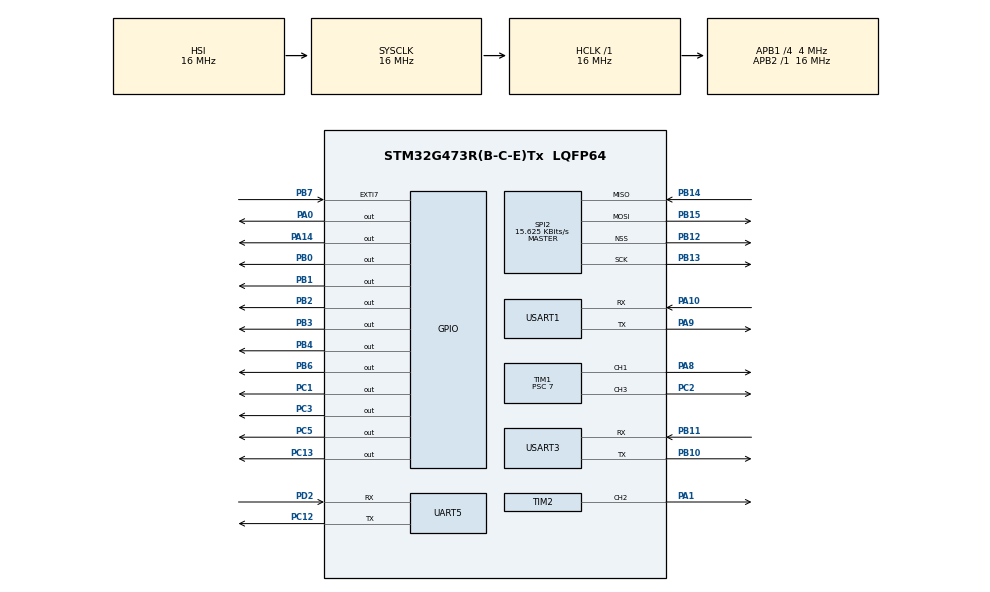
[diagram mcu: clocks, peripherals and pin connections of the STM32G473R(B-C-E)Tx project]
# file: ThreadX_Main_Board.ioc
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Dma.Request0=UART5_RX
Dma.UART5_RX.0.Direction=DMA_PERIPH_TO_MEMORY
Dma.UART5_RX.0.EventEnable=DISABLE
Dma.UART5_RX.0.Instance=DMA1_Channel1
Dma.UART5_RX.0.MemDataAlignment=DMA_MDATAALIGN_BYTE
Dma.UART5_RX.0.MemInc=DMA_MINC_ENABLE
Dma.UART5_RX.0.Mode=DMA_NORMAL
Dma.UART5_RX.0.PeriphDataAlignment=DMA_PDATAALIGN_BYTE
Dma.UART5_RX.0.PeriphInc=DMA_PINC_DISABLE
Dma.UART5_RX.0.Polarity=HAL_DMAMUX_REQ_GEN_RISING
Dma.UART5_RX.0.Priority=DMA_PRIORITY_LOW
Dma.UART5_RX.0.RequestNumber=1
Dma.UART5_RX.0.SignalID=NONE
Dma.UART5_RX.0.SyncEnable=DISABLE
Dma.UART5_RX.0.SyncPolarity=HAL_DMAMUX_SYNC_NO_EVENT
Dma.UART5_RX.0.SyncRequestNumber=1
Dma.UART5_RX.0.SyncSignalID=NONE
Mcu.Family=STM32G4
Mcu.Name=STM32G473R(B-C-E)Tx
Mcu.Package=LQFP64
NVIC.DMA1_Channel1_IRQn=true\:0\:0\:false\:false\:true\:true\:false\:true\:true
NVIC.EXTI9_5_IRQn=true\:0\:0\:false\:false\:true\:false\:true\:true\:true
NVIC.PriorityGroup=NVIC_PRIORITYGROUP_4
NVIC.TIM6_DAC_IRQn=true\:15\:0\:false\:false\:true\:false\:false\:true\:true
NVIC.TimeBase=TIM6_DAC_IRQn
NVIC.TimeBaseIP=TIM6
PA0.Signal=GPIO_Output
PA1.Signal=S_TIM2_CH2
PA10.Mode=Asynchronous
PA10.Signal=USART1_RX
PA14.Signal=GPIO_Output
PA4.Signal=SPI1_NSS
PA8.Signal=S_TIM1_CH1
PA9.Mode=Asynchronous
PA9.Signal=USART1_TX
PB0.Signal=GPIO_Output
PB1.Signal=GPIO_Output
PB10.Mode=Asynchronous
PB10.Signal=USART3_TX
PB11.Mode=Asynchronous
PB11.Signal=USART3_RX
PB12.Mode=NSS_Signal_Hard_Output
PB12.Signal=SPI2_NSS
PB13.Mode=Full_Duplex_Master
PB13.Signal=SPI2_SCK
PB14.Mode=Full_Duplex_Master
PB14.Signal=SPI2_MISO
PB15.Mode=Full_Duplex_Master
PB15.Signal=SPI2_MOSI
PB2.Signal=GPIO_Output
PB3.GPIO_PuPd=GPIO_PULLDOWN
PB3.Signal=GPIO_Output
PB4.Signal=GPIO_Output
PB5.Signal=SPI1_MOSI
PB6.Signal=GPIO_Output
PB7.Signal=GPXTI7
PB9.Signal=I2C1_SDA
PC1.Signal=GPIO_Output
PC12.Mode=Asynchronous
PC12.Signal=UART5_TX
PC13.Signal=GPIO_Output
PC2.Signal=S_TIM1_CH3
PC3.Signal=GPIO_Output
PC5.Signal=GPIO_Output
PD2.Mode=Asynchronous
PD2.Signal=UART5_RX
PF0-OSC_IN.Mode=HSE-External-Oscillator
PF0-OSC_IN.Signal=RCC_OSC_IN
PF1-OSC_OUT.Mode=HSE-External-Oscillator
PF1-OSC_OUT.Signal=RCC_OSC_OUT
ProjectManager.HeapSize=0x200
ProjectManager.StackSize=0x400
ProjectManager.TargetToolchain=STM32CubeIDE
RCC.ADC12Freq_Value=16000000
RCC.ADC345Freq_Value=16000000
RCC.AHBFreq_Value=16000000
RCC.APB1CLKDivider=RCC_HCLK_DIV4
RCC.APB1Freq_Value=4000000
RCC.APB1TimFreq_Value=8000000
RCC.APB2Freq_Value=16000000
RCC.APB2TimFreq_Value=16000000
RCC.CortexFreq_Value=16000000
RCC.EXTERNAL_CLOCK_VALUE=12288000
RCC.HCLKFreq_Value=16000000
RCC.HSE_VALUE=8000000
RCC.HSI48_VALUE=48000000
RCC.HSI_VALUE=16000000
RCC.LSE_VALUE=32768
RCC.SYSCLKFreq_VALUE=16000000
RCC.USBFreq_Value=64000000
RCC.VCOOutputFreq_Value=128000000
SH.S_TIM1_CH1.0=TIM1_CH1,PWM Generation1 CH1
SH.S_TIM1_CH3.0=TIM1_CH3,PWM Generation3 CH3
SH.S_TIM2_CH2.0=TIM2_CH2,PWM Generation2 CH2
SPI2.BaudRatePrescaler=SPI_BAUDRATEPRESCALER_256
SPI2.CalculateBaudRate=15.625 KBits/s
SPI2.DataSize=SPI_DATASIZE_8BIT
SPI2.Direction=SPI_DIRECTION_2LINES
SPI2.Mode=SPI_MODE_MASTER
SPI2.VirtualNSS=VM_NSSHARD
SPI2.VirtualType=VM_MASTER
STMicroelectronics.X-CUBE-AZRTOS-G4.2.0.0.TX_TIMER_TICKS_PER_SECOND=1000
STMicroelectronics.X-CUBE-AZRTOS-G4.2.0.0.ThreadXCcRTOSJjThreadXJjCore=true
STMicroelectronics.X-CUBE-AZRTOS-G4.2.0.0_IsAnAzureRtosMw=true
TIM1.Channel-PWM\ Generation1\ CH1=TIM_CHANNEL_1
TIM1.Channel-PWM\ Generation3\ CH3=TIM_CHANNEL_3
TIM1.PeriodNoDither=255
TIM1.Prescaler=7
TIM2.Channel-PWM\ Generation2\ CH2=TIM_CHANNEL_2
TIM2.PeriodNoDither=255
TIM3.PeriodNoDither=255
TIM3.Prescaler=0
TIM5.PeriodNoDither=255
USART1.VirtualMode-Asynchronous=VM_ASYNC
USART3.VirtualMode-Asynchronous=VM_ASYNC
VP_STMicroelectronics.X-CUBE-AZRTOS-G4_VS_RTOSJjThreadX_6.2.0_2.0.0.Mode=RTOSJjThreadX
VP_SYS_VS_DBSignals.Mode=DisableDeadBatterySignals
VP_SYS_VS_tim6.Mode=TIM6
VP_TIM1_VS_ClockSourceINT.Mode=Internal
VP_TIM3_VS_ClockSourceINT.Mode=Internal
VP_TIM5_VS_ClockSourceINT.Mode=Internal
board=custom

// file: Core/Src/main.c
/* USER CODE BEGIN Header */
/**
 ******************************************************************************
 * @file           : main.c
 * @brief          : Main program body
 ******************************************************************************
 * @attention
 *
 * Copyright (c) 2024 STMicroelectronics.
 * All rights reserved.
 *
 * This software is licensed under terms that can be found in the LICENSE file
 * in the root directory of this software component.
 * If no LICENSE file comes with this software, it is provided AS-IS.
 *
 ******************************************************************************
 */
/* USER CODE END Header */
#include "app_threadx.h"
#include "main.h"

SPI_HandleTypeDef hspi2;

TIM_HandleTypeDef htim1;
TIM_HandleTypeDef htim2;
TIM_HandleTypeDef htim3;
TIM_HandleTypeDef htim5;

UART_HandleTypeDef huart5;
UART_HandleTypeDef huart1;
UART_HandleTypeDef huart3;
DMA_HandleTypeDef hdma_uart5_rx;

void SystemClock_Config(void);
static void MX_GPIO_Init(void);
static void MX_DMA_Init(void);
static void MX_SPI2_Init(void);
static void MX_USART3_UART_Init(void);
static void MX_USART1_UART_Init(void);
static void MX_UART5_Init(void);
static void MX_TIM1_Init(void);
static void MX_TIM3_Init(void);
static void MX_TIM2_Init(void);
static void MX_TIM5_Init(void);

/* USER CODE BEGIN 0 */
void __io_putchar(char ch) {
	HAL_UART_Transmit(&huart1, (uint8_t *)&ch, 1, 10);
}
/* USER CODE END 0 */

int main(void)
{

  /* MCU Configuration--------------------------------------------------------*/

  /* Reset of all peripherals, Initializes the Flash interface and the Systick. */
  HAL_Init();

  /* Configure the system clock */
  SystemClock_Config();

  /* Initialize all configured peripherals */
  MX_GPIO_Init();
  MX_DMA_Init();
  MX_SPI2_Init();
  MX_USART3_UART_Init();
  MX_USART1_UART_Init();
  MX_UART5_Init();
  MX_TIM1_Init();
  MX_TIM3_Init();
  MX_TIM2_Init();
  MX_TIM5_Init();

  MX_ThreadX_Init();

  /* We should never get here as control is now taken by the scheduler */

  /* Infinite loop */
	while (1)
	{

	}
}

void SystemClock_Config(void)
{
  RCC_OscInitTypeDef RCC_OscInitStruct = {0};
  RCC_ClkInitTypeDef RCC_ClkInitStruct = {0};

  /** Configure the main internal regulator output voltage
  */
  HAL_PWREx_ControlVoltageScaling(PWR_REGULATOR_VOLTAGE_SCALE1);

  /** Initializes the RCC Oscillators according to the specified parameters
  * in the RCC_OscInitTypeDef structure.
  */
  RCC_OscInitStruct.OscillatorType = RCC_OSCILLATORTYPE_HSI;
  RCC_OscInitStruct.HSIState = RCC_HSI_ON;
  RCC_OscInitStruct.HSICalibrationValue = RCC_HSICALIBRATION_DEFAULT;
  RCC_OscInitStruct.PLL.PLLState = RCC_PLL_NONE;
  if (HAL_RCC_OscConfig(&RCC_OscInitStruct) != HAL_OK)
  {
    Error_Handler();
  }

  /** Initializes the CPU, AHB and APB buses clocks
  */
  RCC_ClkInitStruct.ClockType = RCC_CLOCKTYPE_HCLK|RCC_CLOCKTYPE_SYSCLK
                              |RCC_CLOCKTYPE_PCLK1|RCC_CLOCKTYPE_PCLK2;
  RCC_ClkInitStruct.SYSCLKSource = RCC_SYSCLKSOURCE_HSI;
  RCC_ClkInitStruct.AHBCLKDivider = RCC_SYSCLK_DIV1;
  RCC_ClkInitStruct.APB1CLKDivider = RCC_HCLK_DIV4;
  RCC_ClkInitStruct.APB2CLKDivider = RCC_HCLK_DIV1;

  if (HAL_RCC_ClockConfig(&RCC_ClkInitStruct, FLASH_LATENCY_0) != HAL_OK)
  {
    Error_Handler();
  }
}

static void MX_SPI2_Init(void)
{

  /* SPI2 parameter configuration*/
  hspi2.Instance = SPI2;
  hspi2.Init.Mode = SPI_MODE_MASTER;
  hspi2.Init.Direction = SPI_DIRECTION_2LINES;
  hspi2.Init.DataSize = SPI_DATASIZE_8BIT;
  hspi2.Init.CLKPolarity = SPI_POLARITY_LOW;
  hspi2.Init.CLKPhase = SPI_PHASE_1EDGE;
  hspi2.Init.NSS = SPI_NSS_HARD_OUTPUT;
  hspi2.Init.BaudRatePrescaler = SPI_BAUDRATEPRESCALER_256;
  hspi2.Init.FirstBit = SPI_FIRSTBIT_MSB;
  hspi2.Init.TIMode = SPI_TIMODE_DISABLE;
  hspi2.Init.CRCCalculation = SPI_CRCCALCULATION_DISABLE;
  hspi2.Init.CRCPolynomial = 7;
  hspi2.Init.CRCLength = SPI_CRC_LENGTH_DATASIZE;
  hspi2.Init.NSSPMode = SPI_NSS_PULSE_ENABLE;
  if (HAL_SPI_Init(&hspi2) != HAL_OK)
  {
    Error_Handler();
  }

}

static void MX_TIM1_Init(void)
{

  TIM_ClockConfigTypeDef sClockSourceConfig = {0};
  TIM_MasterConfigTypeDef sMasterConfig = {0};
  TIM_OC_InitTypeDef sConfigOC = {0};
  TIM_BreakDeadTimeConfigTypeDef sBreakDeadTimeConfig = {0};

  htim1.Instance = TIM1;
  htim1.Init.Prescaler = 7;
  htim1.Init.CounterMode = TIM_COUNTERMODE_UP;
  htim1.Init.Period = 255;
  htim1.Init.ClockDivision = TIM_CLOCKDIVISION_DIV1;
  htim1.Init.RepetitionCounter = 0;
  htim1.Init.AutoReloadPreload = TIM_AUTORELOAD_PRELOAD_DISABLE;
  if (HAL_TIM_Base_Init(&htim1) != HAL_OK)
  {
    Error_Handler();
  }
  sClockSourceConfig.ClockSource = TIM_CLOCKSOURCE_INTERNAL;
  if (HAL_TIM_ConfigClockSource(&htim1, &sClockSourceConfig) != HAL_OK)
  {
    Error_Handler();
  }
  if (HAL_TIM_PWM_Init(&htim1) != HAL_OK)
  {
    Error_Handler();
  }
  sMasterConfig.MasterOutputTrigger = TIM_TRGO_RESET;
  sMasterConfig.MasterOutputTrigger2 = TIM_TRGO2_RESET;
  sMasterConfig.MasterSlaveMode = TIM_MASTERSLAVEMODE_DISABLE;
  if (HAL_TIMEx_MasterConfigSynchronization(&htim1, &sMasterConfig) != HAL_OK)
  {
    Error_Handler();
  }
  sConfigOC.OCMode = TIM_OCMODE_PWM1;
  sConfigOC.Pulse = 0;
  sConfigOC.OCPolarity = TIM_OCPOLARITY_HIGH;
  sConfigOC.OCNPolarity = TIM_OCNPOLARITY_HIGH;
  sConfigOC.OCFastMode = TIM_OCFAST_DISABLE;
  sConfigOC.OCIdleState = TIM_OCIDLESTATE_RESET;
  sConfigOC.OCNIdleState = TIM_OCNIDLESTATE_RESET;
  if (HAL_TIM_PWM_ConfigChannel(&htim1, &sConfigOC, TIM_CHANNEL_1) != HAL_OK)
  {
    Error_Handler();
  }
  if (HAL_TIM_PWM_ConfigChannel(&htim1, &sConfigOC, TIM_CHANNEL_3) != HAL_OK)
  {
    Error_Handler();
  }
  sBreakDeadTimeConfig.OffStateRunMode = TIM_OSSR_DISABLE;
  sBreakDeadTimeConfig.OffStateIDLEMode = TIM_OSSI_DISABLE;
  sBreakDeadTimeConfig.LockLevel = TIM_LOCKLEVEL_OFF;
  sBreakDeadTimeConfig.DeadTime = 0;
  sBreakDeadTimeConfig.BreakState = TIM_BREAK_DISABLE;
  sBreakDeadTimeConfig.BreakPolarity = TIM_BREAKPOLARITY_HIGH;
  sBreakDeadTimeConfig.BreakFilter = 0;
  sBreakDeadTimeConfig.BreakAFMode = TIM_BREAK_AFMODE_INPUT;
  sBreakDeadTimeConfig.Break2State = TIM_BREAK2_DISABLE;
  sBreakDeadTimeConfig.Break2Polarity = TIM_BREAK2POLARITY_HIGH;
  sBreakDeadTimeConfig.Break2Filter = 0;
  sBreakDeadTimeConfig.Break2AFMode = TIM_BREAK_AFMODE_INPUT;
  sBreakDeadTimeConfig.AutomaticOutput = TIM_AUTOMATICOUTPUT_DISABLE;
  if (HAL_TIMEx_ConfigBreakDeadTime(&htim1, &sBreakDeadTimeConfig) != HAL_OK)
  {
    Error_Handler();
  }
  HAL_TIM_MspPostInit(&htim1);

}

static void MX_TIM2_Init(void)
{

  TIM_MasterConfigTypeDef sMasterConfig = {0};
  TIM_OC_InitTypeDef sConfigOC = {0};

  htim2.Instance = TIM2;
  htim2.Init.Prescaler = 0;
  htim2.Init.CounterMode = TIM_COUNTERMODE_UP;
  htim2.Init.Period = 255;
  htim2.Init.ClockDivision = TIM_CLOCKDIVISION_DIV1;
  htim2.Init.AutoReloadPreload = TIM_AUTORELOAD_PRELOAD_DISABLE;
  if (HAL_TIM_PWM_Init(&htim2) != HAL_OK)
  {
    Error_Handler();
  }
  sMasterConfig.MasterOutputTrigger = TIM_TRGO_RESET;
  sMasterConfig.MasterSlaveMode = TIM_MASTERSLAVEMODE_DISABLE;
  if (HAL_TIMEx_MasterConfigSynchronization(&htim2, &sMasterConfig) != HAL_OK)
  {
    Error_Handler();
  }
  sConfigOC.OCMode = TIM_OCMODE_PWM1;
  sConfigOC.Pulse = 0;
  sConfigOC.OCPolarity = TIM_OCPOLARITY_HIGH;
  sConfigOC.OCFastMode = TIM_OCFAST_DISABLE;
  if (HAL_TIM_PWM_ConfigChannel(&htim2, &sConfigOC, TIM_CHANNEL_2) != HAL_OK)
  {
    Error_Handler();
  }
  HAL_TIM_MspPostInit(&htim2);

}

static void MX_TIM3_Init(void)
{

  TIM_ClockConfigTypeDef sClockSourceConfig = {0};
  TIM_MasterConfigTypeDef sMasterConfig = {0};

  htim3.Instance = TIM3;
  htim3.Init.Prescaler = 0;
  htim3.Init.CounterMode = TIM_COUNTERMODE_UP;
  htim3.Init.Period = 255;
  htim3.Init.ClockDivision = TIM_CLOCKDIVISION_DIV1;
  htim3.Init.AutoReloadPreload = TIM_AUTORELOAD_PRELOAD_DISABLE;
  if (HAL_TIM_Base_Init(&htim3) != HAL_OK)
  {
    Error_Handler();
  }
  sClockSourceConfig.ClockSource = TIM_CLOCKSOURCE_INTERNAL;
  if (HAL_TIM_ConfigClockSource(&htim3, &sClockSourceConfig) != HAL_OK)
  {
    Error_Handler();
  }
  sMasterConfig.MasterOutputTrigger = TIM_TRGO_RESET;
  sMasterConfig.MasterSlaveMode = TIM_MASTERSLAVEMODE_DISABLE;
  if (HAL_TIMEx_MasterConfigSynchronization(&htim3, &sMasterConfig) != HAL_OK)
  {
    Error_Handler();
  }

}

static void MX_TIM5_Init(void)
{

  TIM_ClockConfigTypeDef sClockSourceConfig = {0};
  TIM_MasterConfigTypeDef sMasterConfig = {0};

  htim5.Instance = TIM5;
  htim5.Init.Prescaler = 0;
  htim5.Init.CounterMode = TIM_COUNTERMODE_UP;
  htim5.Init.Period = 255;
  htim5.Init.ClockDivision = TIM_CLOCKDIVISION_DIV1;
  htim5.Init.AutoReloadPreload = TIM_AUTORELOAD_PRELOAD_DISABLE;
  if (HAL_TIM_Base_Init(&htim5) != HAL_OK)
  {
    Error_Handler();
  }
  sClockSourceConfig.ClockSource = TIM_CLOCKSOURCE_INTERNAL;
  if (HAL_TIM_ConfigClockSource(&htim5, &sClockSourceConfig) != HAL_OK)
  {
    Error_Handler();
  }
  sMasterConfig.MasterOutputTrigger = TIM_TRGO_RESET;
  sMasterConfig.MasterSlaveMode = TIM_MASTERSLAVEMODE_DISABLE;
  if (HAL_TIMEx_MasterConfigSynchronization(&htim5, &sMasterConfig) != HAL_OK)
  {
    Error_Handler();
  }

}

static void MX_UART5_Init(void)
{

  huart5.Instance = UART5;
  huart5.Init.BaudRate = 115200;
  huart5.Init.WordLength = UART_WORDLENGTH_8B;
  huart5.Init.StopBits = UART_STOPBITS_1;
  huart5.Init.Parity = UART_PARITY_NONE;
  huart5.Init.Mode = UART_MODE_TX_RX;
  huart5.Init.HwFlowCtl = UART_HWCONTROL_NONE;
  huart5.Init.OverSampling = UART_OVERSAMPLING_16;
  huart5.Init.OneBitSampling = UART_ONE_BIT_SAMPLE_DISABLE;
  huart5.Init.ClockPrescaler = UART_PRESCALER_DIV1;
  huart5.AdvancedInit.AdvFeatureInit = UART_ADVFEATURE_NO_INIT;
  if (HAL_UART_Init(&huart5) != HAL_OK)
  {
    Error_Handler();
  }
  if (HAL_UARTEx_SetTxFifoThreshold(&huart5, UART_TXFIFO_THRESHOLD_1_8) != HAL_OK)
  {
    Error_Handler();
  }
  if (HAL_UARTEx_SetRxFifoThreshold(&huart5, UART_RXFIFO_THRESHOLD_1_8) != HAL_OK)
  {
    Error_Handler();
  }
  if (HAL_UARTEx_DisableFifoMode(&huart5) != HAL_OK)
  {
    Error_Handler();
  }

}

static void MX_USART1_UART_Init(void)
{

  huart1.Instance = USART1;
  huart1.Init.BaudRate = 115200;
  huart1.Init.WordLength = UART_WORDLENGTH_8B;
  huart1.Init.StopBits = UART_STOPBITS_1;
  huart1.Init.Parity = UART_PARITY_NONE;
  huart1.Init.Mode = UART_MODE_TX_RX;
  huart1.Init.HwFlowCtl = UART_HWCONTROL_NONE;
  huart1.Init.OverSampling = UART_OVERSAMPLING_16;
  huart1.Init.OneBitSampling = UART_ONE_BIT_SAMPLE_DISABLE;
  huart1.Init.ClockPrescaler = UART_PRESCALER_DIV1;
  huart1.AdvancedInit.AdvFeatureInit = UART_ADVFEATURE_NO_INIT;
  if (HAL_UART_Init(&huart1) != HAL_OK)
  {
    Error_Handler();
  }
  if (HAL_UARTEx_SetTxFifoThreshold(&huart1, UART_TXFIFO_THRESHOLD_1_8) != HAL_OK)
  {
    Error_Handler();
  }
  if (HAL_UARTEx_SetRxFifoThreshold(&huart1, UART_RXFIFO_THRESHOLD_1_8) != HAL_OK)
  {
    Error_Handler();
  }
  if (HAL_UARTEx_DisableFifoMode(&huart1) != HAL_OK)
  {
    Error_Handler();
  }

}

static void MX_USART3_UART_Init(void)
{

  huart3.Instance = USART3;
  huart3.Init.BaudRate = 115200;
  huart3.Init.WordLength = UART_WORDLENGTH_8B;
  huart3.Init.StopBits = UART_STOPBITS_1;
  huart3.Init.Parity = UART_PARITY_NONE;
  huart3.Init.Mode = UART_MODE_TX_RX;
  huart3.Init.HwFlowCtl = UART_HWCONTROL_NONE;
  huart3.Init.OverSampling = UART_OVERSAMPLING_16;
  huart3.Init.OneBitSampling = UART_ONE_BIT_SAMPLE_DISABLE;
  huart3.Init.ClockPrescaler = UART_PRESCALER_DIV1;
  huart3.AdvancedInit.AdvFeatureInit = UART_ADVFEATURE_NO_INIT;
  if (HAL_UART_Init(&huart3) != HAL_OK)
  {
    Error_Handler();
  }
  if (HAL_UARTEx_SetTxFifoThreshold(&huart3, UART_TXFIFO_THRESHOLD_1_8) != HAL_OK)
  {
    Error_Handler();
  }
  if (HAL_UARTEx_SetRxFifoThreshold(&huart3, UART_RXFIFO_THRESHOLD_1_8) != HAL_OK)
  {
    Error_Handler();
  }
  if (HAL_UARTEx_DisableFifoMode(&huart3) != HAL_OK)
  {
    Error_Handler();
  }

}

static void MX_DMA_Init(void)
{

  /* DMA controller clock enable */
  __HAL_RCC_DMAMUX1_CLK_ENABLE();
  __HAL_RCC_DMA1_CLK_ENABLE();

  /* DMA interrupt init */
  /* DMA1_Channel1_IRQn interrupt configuration */
  HAL_NVIC_SetPriority(DMA1_Channel1_IRQn, 0, 0);
  HAL_NVIC_EnableIRQ(DMA1_Channel1_IRQn);

}

static void MX_GPIO_Init(void)
{
  GPIO_InitTypeDef GPIO_InitStruct = {0};

  /* GPIO Ports Clock Enable */
  __HAL_RCC_GPIOC_CLK_ENABLE();
  __HAL_RCC_GPIOF_CLK_ENABLE();
  __HAL_RCC_GPIOA_CLK_ENABLE();
  __HAL_RCC_GPIOB_CLK_ENABLE();
  __HAL_RCC_GPIOD_CLK_ENABLE();

  /*Configure GPIO pin Output Level */
  HAL_GPIO_WritePin(GPIOC, GPIO_PIN_13|GPIO_PIN_1|GPIO_PIN_3|GPIO_PIN_5, GPIO_PIN_RESET);

  /*Configure GPIO pin Output Level */
  HAL_GPIO_WritePin(GPIOA, GPIO_PIN_0|GPIO_PIN_14, GPIO_PIN_RESET);

  /*Configure GPIO pin Output Level */
  HAL_GPIO_WritePin(GPIOB, GPIO_PIN_0|GPIO_PIN_1|GPIO_PIN_2|GPIO_PIN_3
                          |GPIO_PIN_4|GPIO_PIN_6, GPIO_PIN_RESET);

  /*Configure GPIO pins : PC13 PC1 PC3 PC5 */
  GPIO_InitStruct.Pin = GPIO_PIN_13|GPIO_PIN_1|GPIO_PIN_3|GPIO_PIN_5;
  GPIO_InitStruct.Mode = GPIO_MODE_OUTPUT_PP;
  GPIO_InitStruct.Pull = GPIO_NOPULL;
  GPIO_InitStruct.Speed = GPIO_SPEED_FREQ_LOW;
  HAL_GPIO_Init(GPIOC, &GPIO_InitStruct);

  /*Configure GPIO pins : PA0 PA14 */
  GPIO_InitStruct.Pin = GPIO_PIN_0|GPIO_PIN_14;
  GPIO_InitStruct.Mode = GPIO_MODE_OUTPUT_PP;
  GPIO_InitStruct.Pull = GPIO_NOPULL;
  GPIO_InitStruct.Speed = GPIO_SPEED_FREQ_LOW;
  HAL_GPIO_Init(GPIOA, &GPIO_InitStruct);

  /*Configure GPIO pin : PA4 */
  GPIO_InitStruct.Pin = GPIO_PIN_4;
  GPIO_InitStruct.Mode = GPIO_MODE_AF_PP;
  GPIO_InitStruct.Pull = GPIO_NOPULL;
  GPIO_InitStruct.Speed = GPIO_SPEED_FREQ_LOW;
  GPIO_InitStruct.Alternate = GPIO_AF5_SPI1;
  HAL_GPIO_Init(GPIOA, &GPIO_InitStruct);

  /*Configure GPIO pins : PB0 PB1 PB2 PB4
                           PB6 */
  GPIO_InitStruct.Pin = GPIO_PIN_0|GPIO_PIN_1|GPIO_PIN_2|GPIO_PIN_4
                          |GPIO_PIN_6;
  GPIO_InitStruct.Mode = GPIO_MODE_OUTPUT_PP;
  GPIO_InitStruct.Pull = GPIO_NOPULL;
  GPIO_InitStruct.Speed = GPIO_SPEED_FREQ_LOW;
  HAL_GPIO_Init(GPIOB, &GPIO_InitStruct);

  /*Configure GPIO pin : PB3 */
  GPIO_InitStruct.Pin = GPIO_PIN_3;
  GPIO_InitStruct.Mode = GPIO_MODE_OUTPUT_PP;
  GPIO_InitStruct.Pull = GPIO_PULLDOWN;
  GPIO_InitStruct.Speed = GPIO_SPEED_FREQ_LOW;
  HAL_GPIO_Init(GPIOB, &GPIO_InitStruct);

  /*Configure GPIO pin : PB5 */
  GPIO_InitStruct.Pin = GPIO_PIN_5;
  GPIO_InitStruct.Mode = GPIO_MODE_AF_PP;
  GPIO_InitStruct.Pull = GPIO_NOPULL;
  GPIO_InitStruct.Speed = GPIO_SPEED_FREQ_LOW;
  GPIO_InitStruct.Alternate = GPIO_AF5_SPI1;
  HAL_GPIO_Init(GPIOB, &GPIO_InitStruct);

  /*Configure GPIO pin : PB7 */
  GPIO_InitStruct.Pin = GPIO_PIN_7;
  GPIO_InitStruct.Mode = GPIO_MODE_IT_RISING;
  GPIO_InitStruct.Pull = GPIO_NOPULL;
  HAL_GPIO_Init(GPIOB, &GPIO_InitStruct);

  /*Configure GPIO pin : PB9 */
  GPIO_InitStruct.Pin = GPIO_PIN_9;
  GPIO_InitStruct.Mode = GPIO_MODE_AF_OD;
  GPIO_InitStruct.Pull = GPIO_NOPULL;
  GPIO_InitStruct.Speed = GPIO_SPEED_FREQ_LOW;
  GPIO_InitStruct.Alternate = GPIO_AF4_I2C1;
  HAL_GPIO_Init(GPIOB, &GPIO_InitStruct);

  /* EXTI interrupt init*/
  HAL_NVIC_SetPriority(EXTI9_5_IRQn, 0, 0);
  HAL_NVIC_EnableIRQ(EXTI9_5_IRQn);

}

void HAL_TIM_PeriodElapsedCallback(TIM_HandleTypeDef *htim)
{
  if (htim->Instance == TIM6) {
    HAL_IncTick();
  }
}

void Error_Handler(void)
{
	__disable_irq();
	while (1)
	{
	}
}
